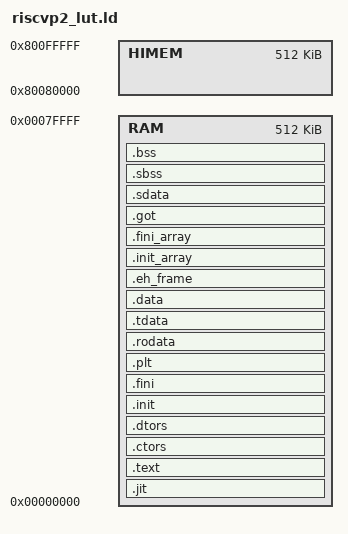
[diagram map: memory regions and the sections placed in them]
/* Default linker script, for normal executables */
/* modified to link to 0x0 and include P2 rv32imc emulator */
/* further modified to simplify */
/* Copyright (C) 2014-2019 Free Software Foundation, Inc.
   Copying and distribution of this script, with or without modification,
   are permitted in any medium without royalty provided the copyright
   notice and this notice are preserved.  */
OUTPUT_FORMAT("elf32-littleriscv", "elf32-littleriscv",
	      "elf32-littleriscv")
OUTPUT_ARCH(riscv)
ENTRY(_start)
SEARCH_DIR("=/lib");
GROUP(-lc -lgloss)
STARTUP("rvp2_lut.o")
/* memory layout: the P2 Eval board has 512K of RAM, and 1 MB of flash
   of which the second 512K is allocated as execute in place (xip)
 */
MEMORY
{
  RAM : ORIGIN = 0x00000000, LENGTH = 512K
  HIMEM : ORIGIN = 0x80080000, LENGTH = 512K
}

REGION_ALIAS("REGION_JIT", RAM);
REGION_ALIAS("REGION_TEXT", RAM);
REGION_ALIAS("REGION_RODATA", RAM);
REGION_ALIAS("REGION_DATA", RAM);
REGION_ALIAS("REGION_BSS", RAM);

/* the stuff below should be the same for all */
SECTIONS
{
  .jit            :
  {
    KEEP(*(.jitkernel))
    KEEP(*(.jittext))
  } > REGION_JIT  
  .text           :
  {
    *(.text .stub .text.* .gnu.linkonce.t.*)
    *(.text.unlikely .text.*_unlikely .text.unlikely.*)
    *(.text.exit .text.exit.*)
    *(.text.startup .text.startup.*)
    *(.text.hot .text.hot.*)
    /* .gnu.warning sections are handled specially by elf32.em.  */
    *(.gnu.warning)

    PROVIDE (__etext = .);
    PROVIDE (_etext = .);
    PROVIDE (etext = .);
  } > REGION_TEXT
  .ctors          :
  {
    /* gcc uses crtbegin.o to find the start of
       the constructors, so we make sure it is
       first.  Because this is a wildcard, it
       doesn't matter if the user does not
       actually link against crtbegin.o; the
       linker won't look for a file to match a
       wildcard.  The wildcard also means that it
       doesn't matter which directory crtbegin.o
       is in.  */
    KEEP (*crtbegin.o(.ctors))
    KEEP (*crtbegin?.o(.ctors))
    /* We don't want to include the .ctor section from
       the crtend.o file until after the sorted ctors.
       The .ctor section from the crtend file contains the
       end of ctors marker and it must be last */
    KEEP (*(EXCLUDE_FILE (*crtend.o *crtend?.o ) .ctors))
    KEEP (*(SORT(.ctors.*)))
    KEEP (*(.ctors))
  } > REGION_TEXT
  .dtors          :
  {
    KEEP (*crtbegin.o(.dtors))
    KEEP (*crtbegin?.o(.dtors))
    KEEP (*(EXCLUDE_FILE (*crtend.o *crtend?.o ) .dtors))
    KEEP (*(SORT(.dtors.*)))
    KEEP (*(.dtors))
  } > REGION_TEXT
  .init           :
  {
    KEEP (*(SORT_NONE(.init)))
  } > REGION_TEXT
  .fini           :
  {
    KEEP (*(SORT_NONE(.fini)))
  } > REGION_TEXT
  .plt            :
  {
    *(.plt)
    *(.iplt)
  } > REGION_TEXT
  .rodata         :
  {
    *(.plt)
    *(.iplt)
    *(.rodata .rodata.* .gnu.linkonce.r.*)
  } > REGION_RODATA
  
  /* Thread Local Storage sections  */
  .tdata	  :
   {
     PROVIDE_HIDDEN (__tdata_start = .);
     *(.tdata .tdata.* .gnu.linkonce.td.*)
   } > REGION_DATA
  .data           :
  {
    __DATA_BEGIN__ = .;
    *(.data .data.* .gnu.linkonce.d.*)
    SORT(CONSTRUCTORS)
  } > REGION_DATA
  .eh_frame      :
  {
    KEEP (*(.eh_frame)) *(.eh_frame.*)
  } > REGION_DATA
  .init_array    :
  {
    PROVIDE_HIDDEN (__init_array_start = .);
    KEEP (*(SORT_BY_INIT_PRIORITY(.init_array.*) SORT_BY_INIT_PRIORITY(.ctors.*)))
    KEEP (*(.init_array EXCLUDE_FILE (*crtbegin.o *crtbegin?.o *crtend.o *crtend?.o ) .ctors))
    PROVIDE_HIDDEN (__init_array_end = .);
  } > REGION_DATA
  .fini_array    :
  {
    PROVIDE_HIDDEN (__fini_array_start = .);
    KEEP (*(SORT_BY_INIT_PRIORITY(.fini_array.*) SORT_BY_INIT_PRIORITY(.dtors.*)))
    KEEP (*(.fini_array EXCLUDE_FILE (*crtbegin.o *crtbegin?.o *crtend.o *crtend?.o ) .dtors))
    PROVIDE_HIDDEN (__fini_array_end = .);
  } > REGION_DATA
  .got            : { *(.got.plt) *(.igot.plt) *(.got) *(.igot) } > REGION_DATA
  /* We want the small data sections together, so single-instruction offsets
     can access them all, and initialized data all before uninitialized, so
     we can shorten the on-disk segment size.  */
  .sdata          :
  {
    __SDATA_BEGIN__ = .;
    *(.srodata.cst16) *(.srodata.cst8) *(.srodata.cst4) *(.srodata.cst2) *(.srodata .srodata.*)
    *(.sdata .sdata.* .gnu.linkonce.s.*)
    _edata = .; PROVIDE (edata = .);
  } > REGION_DATA
  .sbss           :
  {
    __bss_start = .;
    *(.dynsbss)
    *(.sbss .sbss.* .gnu.linkonce.sb.*)
    *(.scommon)
  } > REGION_BSS
  .bss            :
  {
   *(.dynbss)
   *(.bss .bss.* .gnu.linkonce.b.*)
   *(COMMON)
   /* Align here to ensure that the .bss section occupies space up to
      _end.  Align after .bss to ensure correct alignment even if the
      .bss section disappears because there are no input sections.
      FIXME: Why do we need it? When there is no .bss section, we do not
      pad the .data section.  */
   . = ALIGN(. != 0 ? 32 / 8 : 1);
  } > REGION_DATA
  . = ALIGN(32 / 8);
  __BSS_END__ = .;
    __global_pointer$ = MIN(__SDATA_BEGIN__ + 0x800,
		            MAX(__DATA_BEGIN__ + 0x800, __BSS_END__ - 0x800));
  _end = .; PROVIDE (end = .);

  /* Stabs debugging sections.  */
  .stab          0 : { *(.stab) }
  .stabstr       0 : { *(.stabstr) }
  .stab.excl     0 : { *(.stab.excl) }
  .stab.exclstr  0 : { *(.stab.exclstr) }
  .stab.index    0 : { *(.stab.index) }
  .stab.indexstr 0 : { *(.stab.indexstr) }
  .comment       0 : { *(.comment) }
  .gnu.build.attributes : { *(.gnu.build.attributes .gnu.build.attributes.*) }
  /* DWARF debug sections.
     Symbols in the DWARF debugging sections are relative to the beginning
     of the section so we begin them at 0.  */
  /* DWARF 1 */
  .debug          0 : { *(.debug) }
  .line           0 : { *(.line) }
  /* GNU DWARF 1 extensions */
  .debug_srcinfo  0 : { *(.debug_srcinfo) }
  .debug_sfnames  0 : { *(.debug_sfnames) }
  /* DWARF 1.1 and DWARF 2 */
  .debug_aranges  0 : { *(.debug_aranges) }
  .debug_pubnames 0 : { *(.debug_pubnames) }
  /* DWARF 2 */
  .debug_info     0 : { *(.debug_info .gnu.linkonce.wi.*) }
  .debug_abbrev   0 : { *(.debug_abbrev) }
  .debug_line     0 : { *(.debug_line .debug_line.* .debug_line_end) }
  .debug_frame    0 : { *(.debug_frame) }
  .debug_str      0 : { *(.debug_str) }
  .debug_loc      0 : { *(.debug_loc) }
  .debug_macinfo  0 : { *(.debug_macinfo) }
  /* SGI/MIPS DWARF 2 extensions */
  .debug_weaknames 0 : { *(.debug_weaknames) }
  .debug_funcnames 0 : { *(.debug_funcnames) }
  .debug_typenames 0 : { *(.debug_typenames) }
  .debug_varnames  0 : { *(.debug_varnames) }
  /* DWARF 3 */
  .debug_pubtypes 0 : { *(.debug_pubtypes) }
  .debug_ranges   0 : { *(.debug_ranges) }
  /* DWARF Extension.  */
  .debug_macro    0 : { *(.debug_macro) }
  .debug_addr     0 : { *(.debug_addr) }
  .gnu.attributes 0 : { KEEP (*(.gnu.attributes)) }
  /DISCARD/ : { *(.note.GNU-stack) *(.gnu_debuglink) *(.gnu.lto_*) }
}
